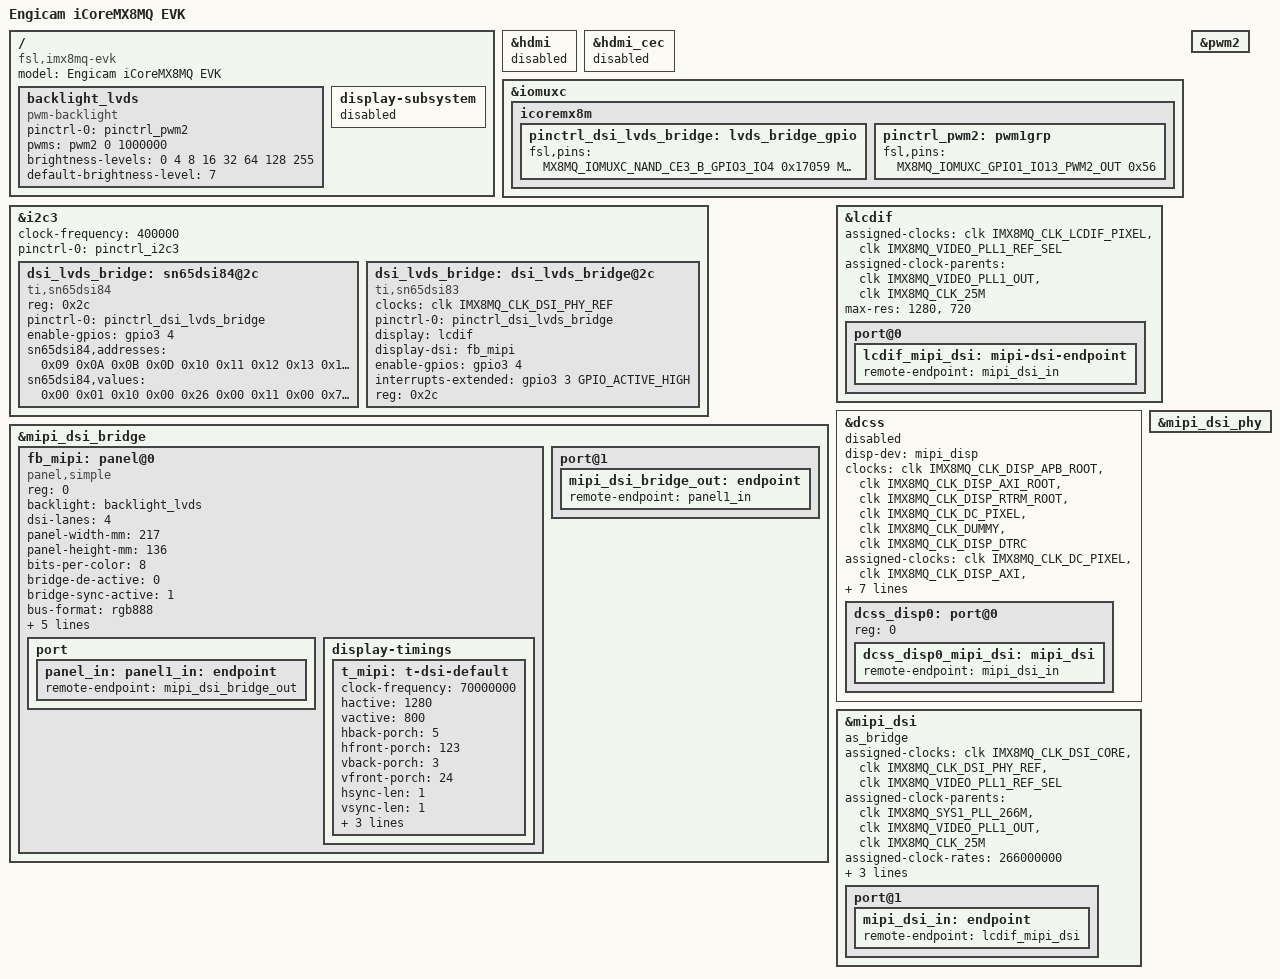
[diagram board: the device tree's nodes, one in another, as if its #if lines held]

/ {
	model = "Engicam iCoreMX8MQ EVK";
	compatible = "fsl,imx8mq-evk", "fsl,imx8mq";
        
        backlight_lvds: backlight_lvds {
                compatible = "pwm-backlight";
                pinctrl-names = "default";
                pinctrl-0 = <&pinctrl_pwm2>;
                pwms = <&pwm2 0 1000000>;
                brightness-levels = <0 4 8 16 32 64 128 255>;
                default-brightness-level = <7>;
                status = "okay";
        };

	display-subsystem {
		status = "disabled";
	};

};

&hdmi {
	status = "disabled";
};

#ifdef TOLTO_MM
&hdmi_cec {
	status = "disabled";
};
#endif

&iomuxc {
	icoremx8m {
        pinctrl_dsi_lvds_bridge: lvds_bridge_gpio {
            fsl,pins = <
                MX8MQ_IOMUXC_NAND_CE3_B_GPIO3_IO4	0x17059
				MX8MQ_IOMUXC_NAND_CE2_B_GPIO3_IO3	0x17059
            >;
        };
        
        pinctrl_pwm2: pwm1grp {
                fsl,pins = <
                        MX8MQ_IOMUXC_GPIO1_IO13_PWM2_OUT                0x56
                >;
        };

    };    
};


&pwm2{

    status = "okay";
    
};

&i2c3 {
	clock-frequency = <400000>;
	pinctrl-names = "default";
	pinctrl-0 = <&pinctrl_i2c3>;
	status = "okay";

#ifdef TOLTO_MM    
	dsi_lvds_bridge: sn65dsi84@2c {
		reg = <0x2c>;
		status = "okay";
		pinctrl-names = "default";
		pinctrl-0 = <&pinctrl_dsi_lvds_bridge>;
		compatible = "ti,sn65dsi84";
		
        enable-gpios = <&gpio3 4  GPIO_ACTIVE_HIGH>;

		sn65dsi84,addresses = <	0x09 0x0A 0x0B 0x0D 0x10 0x11 0x12 0x13
					0x18 0x19 0x1A 0x1B 0x20 0x21 0x22 0x23
					0x24 0x25 0x26 0x27 0x28 0x29 0x2A 0x2B
					0x2C 0x2D 0x2E 0x2F 0x30 0x31 0x32 0x33
					0x34 0x35 0x36 0x37 0x38 0x39 0x3A 0x3B
					0x3C 0x3D 0x3E 0x0D>;

		sn65dsi84,values =    <	0x00 0x01 0x10 0x00 0x26 0x00 0x11 0x00
					0x7a 0x00 0x03 0x00 0x20 0x03 0x00 0x00
					0x00 0x00 0x00 0x00 0x21 0x00 0x00 0x00
					0x30 0x00 0x00 0x00 0x03 0x00 0x00 0x00
					0x28 0x00 0x00 0x00 0x00 0x00 0x00 0x00
					0x00 0x00 0x00 0x01>;
	};
#endif

	dsi_lvds_bridge: dsi_lvds_bridge@2c {
		clocks = <&clk IMX8MQ_CLK_DSI_PHY_REF>;
		clock-names = "mipi_clk";
		pinctrl-names = "default";
		pinctrl-0 = <&pinctrl_dsi_lvds_bridge>;
		compatible = "ti,sn65dsi83";
		display = <&lcdif>;
		display-dsi = <&fb_mipi>;
		enable-gpios = <&gpio3 4  GPIO_ACTIVE_HIGH>;
		interrupts-extended = <&gpio3 3  GPIO_ACTIVE_HIGH>;
		reg = <0x2c>;
		status = "okay";
	};

};

#ifdef TOLTO_MM
&mipi_dsi_bridge {

	status = "okay";
	panel@0 {
                reg = <0>;
                status = "okay";
                compatible = "sgd,gktw70sdae4sd";
                backlight = <&backlight_lvds>;

                dsi-lanes = <4>;
                panel-width-mm  = <800>;
                panel-height-mm = <480>;

                port {
                    panel_in: endpoint {
                        remote-endpoint = <&mipi_dsi_bridge_out>;
                    };
                };
	};

	port@1 {
		mipi_dsi_bridge_out: endpoint {
			remote-endpoint = <&panel_in>;
		};
	};
	
};
#endif

#ifdef TOLTO_MM
&dsi_lvds_bridge {
	status = "okay";
};
#endif

&lcdif {
	status = "okay";
	assigned-clocks = <&clk IMX8MQ_CLK_LCDIF_PIXEL>,
			  <&clk IMX8MQ_VIDEO_PLL1_REF_SEL>;
	assigned-clock-parents = <&clk IMX8MQ_VIDEO_PLL1_OUT>,
				 <&clk IMX8MQ_CLK_25M>;
	max-res = <1280>, <720>;

	port@0 {
		lcdif_mipi_dsi: mipi-dsi-endpoint {
			remote-endpoint = <&mipi_dsi_in>;
		};
	};
};

#ifdef TOLTO_MM
&dcss {
	status = "disabled";
	disp-dev = "mipi_disp";

	
	clocks = <&clk IMX8MQ_CLK_DISP_APB_ROOT>,
		 <&clk IMX8MQ_CLK_DISP_AXI_ROOT>,
		 <&clk IMX8MQ_CLK_DISP_RTRM_ROOT>,
		 <&clk IMX8MQ_CLK_DC_PIXEL>,
		 <&clk IMX8MQ_CLK_DUMMY>,
		 <&clk IMX8MQ_CLK_DISP_DTRC>;
	clock-names = "apb", "axi", "rtrm", "pix_div", "pix_out", "dtrc";
	assigned-clocks = <&clk IMX8MQ_CLK_DC_PIXEL>,
			  <&clk IMX8MQ_CLK_DISP_AXI>,
			  <&clk IMX8MQ_CLK_DISP_RTRM>;
	assigned-clock-parents = <&clk IMX8MQ_VIDEO_PLL1_OUT>,
				 <&clk IMX8MQ_SYS1_PLL_800M>,
				 <&clk IMX8MQ_SYS1_PLL_800M>;
	assigned-clock-rates = <594000000>,
			       <800000000>,
			       <400000000>;

	
	dcss_disp0: port@0 {
		reg = <0>;

		dcss_disp0_mipi_dsi: mipi_dsi {
			remote-endpoint = <&mipi_dsi_in>;
		};
	};
};

#endif

&mipi_dsi_phy {
	status = "okay";
};

&mipi_dsi {
	status = "okay";
	as_bridge;
	assigned-clocks = <&clk IMX8MQ_CLK_DSI_CORE>,
			  <&clk IMX8MQ_CLK_DSI_PHY_REF>,
			  <&clk IMX8MQ_VIDEO_PLL1_REF_SEL>;
	assigned-clock-parents = <&clk IMX8MQ_SYS1_PLL_266M>,
				 <&clk IMX8MQ_VIDEO_PLL1_OUT>,
				 <&clk IMX8MQ_CLK_25M>;
	assigned-clock-rates = <266000000>;

	clocks = <&clk IMX8MQ_CLK_DSI_CORE>,
		 <&clk IMX8MQ_CLK_DSI_PHY_REF>,
		 <&clk IMX8MQ_VIDEO_PLL1>;
	clock-names = "core", "phy_ref", "pixel_pll";
	
	port@1 {
		mipi_dsi_in: endpoint {
			remote-endpoint = <&lcdif_mipi_dsi>;
		};
	};
};

&mipi_dsi_bridge {
	status = "okay";

	fb_mipi: panel@0 {
		bits-per-color = <8>;
		bridge-de-active = <0>;
		bridge-sync-active = <1>;
		bus-format = "rgb888";
		compatible = "panel,simple";
		dsi-format = "rgb888";
		dsi-lanes = <4>;
		mode-skip-eot;
		mode-video;
		mode-video-burst;
		panel-height-mm = <136>;
		panel-width-mm = <217>;
//		power-supply = <&reg_vref_5v>;
//		reg = <0>;
		spwg;

		display-timings {
			t_mipi: t-dsi-default {
				/* m101nwwb by default */
				clock-frequency = <70000000>;
				hactive = <1280>;
				vactive = <800>;
				hback-porch = <5>;
				hfront-porch = <123>;
				vback-porch = <3>;
				vfront-porch = <24>;
				hsync-len = <1>;
				vsync-len = <1>;
				hsync-active = <0>;
				vsync-active = <0>;
				de-active = <1>;
			};
		};

		port {
			panel1_in: endpoint {
				remote-endpoint = <&mipi_dsi_bridge_out>;
			};
		};
	};

	port@1 {
		mipi_dsi_bridge_out: endpoint {
			remote-endpoint = <&panel1_in>;
		};
	};
};
